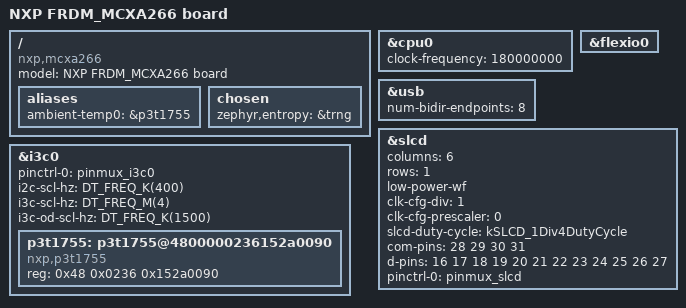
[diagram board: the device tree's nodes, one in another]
/*
 * Copyright 2025 NXP
 *
 * SPDX-License-Identifier: Apache-2.0
 */

/dts-v1/;

#include <nxp/mcx/nxp_mcxa266.dtsi>
#include "frdm_mcxa266-pinctrl.dtsi"
#include "board_common.dtsi"
#include <freq.h>

/ {
	model = "NXP FRDM_MCXA266 board";
	compatible = "nxp,mcxa266", "nxp,mcx";

	aliases {
		ambient-temp0 = &p3t1755;
	};

	chosen {
		zephyr,entropy = &trng;
	};
};

&cpu0 {
	clock-frequency = <180000000>;
};

&i3c0 {
	status = "okay";
	pinctrl-0 = <&pinmux_i3c0>;
	pinctrl-names = "default";

	i2c-scl-hz = <DT_FREQ_K(400)>;
	i3c-scl-hz = <DT_FREQ_M(4)>;
	i3c-od-scl-hz = <DT_FREQ_K(1500)>;

	p3t1755: p3t1755@4800000236152a0090 {
		compatible = "nxp,p3t1755";
		reg = <0x48 0x0236 0x152a0090>;
		status = "okay";
	};
};

&flexio0 {
	status = "okay";
};

zephyr_udc0: &usb {
	status = "okay";
	num-bidir-endpoints = <8>;
};

auxdisplay0: &slcd {
	status = "okay";

	/* 6 digits, 1 row */
	columns = <6>;
	rows = <1>;
	low-power-wf;
	clk-cfg-div = <1>;
	clk-cfg-prescaler = <0>;
	slcd-duty-cycle = "kSLCD_1Div4DutyCycle";

	com-pins = /bits/ 8 <28 29 30 31>;
	d-pins = /bits/ 8 <16 17 18 19 20 21 22 23 24 25 26 27>;

	pinctrl-0 = <&pinmux_slcd>;
	pinctrl-names = "default";
};
